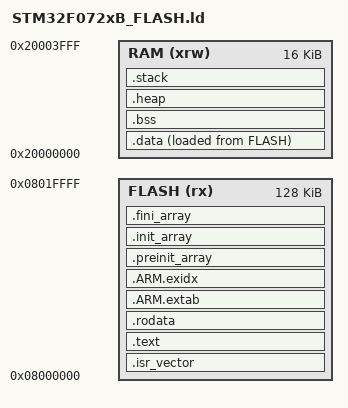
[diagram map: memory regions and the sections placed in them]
ENTRY(Reset_Handler)

MEMORY
{
  FLASH (rx)  : ORIGIN = 0x08000000, LENGTH = 128K
  RAM (xrw)   : ORIGIN = 0x20000000, LENGTH = 16K
}

_estack = ORIGIN(RAM) + LENGTH(RAM);

SECTIONS
{
  .isr_vector :
  {
    . = ALIGN(4);
    KEEP(*(.isr_vector))
    . = ALIGN(4);
  } > FLASH

  .text :
  {
    . = ALIGN(4);
    *(.text .text*)
    *(.glue_7 .glue_7t)
    *(.eh_frame)
    KEEP(*(.init))
    KEEP(*(.fini))
    . = ALIGN(4);
    _etext = .;
  } > FLASH

  .rodata :
  {
    . = ALIGN(4);
    *(.rodata .rodata*)
    . = ALIGN(4);
  } > FLASH

  .ARM.extab :
  {
    . = ALIGN(4);
    *(.ARM.extab* .gnu.linkonce.armextab.*)
    . = ALIGN(4);
  } > FLASH

  .ARM.exidx :
  {
    . = ALIGN(4);
    __exidx_start = .;
    *(.ARM.exidx* .gnu.linkonce.armexidx.*)
    __exidx_end = .;
    . = ALIGN(4);
  } > FLASH

  .preinit_array :
  {
    . = ALIGN(4);
    PROVIDE_HIDDEN(__preinit_array_start = .);
    KEEP(*(.preinit_array*))
    PROVIDE_HIDDEN(__preinit_array_end = .);
    . = ALIGN(4);
  } > FLASH

  .init_array :
  {
    . = ALIGN(4);
    PROVIDE_HIDDEN(__init_array_start = .);
    KEEP(*(SORT(.init_array.*)))
    KEEP(*(.init_array*))
    PROVIDE_HIDDEN(__init_array_end = .);
    . = ALIGN(4);
  } > FLASH

  .fini_array :
  {
    . = ALIGN(4);
    PROVIDE_HIDDEN(__fini_array_start = .);
    KEEP(*(SORT(.fini_array.*)))
    KEEP(*(.fini_array*))
    PROVIDE_HIDDEN(__fini_array_end = .);
    . = ALIGN(4);
  } > FLASH

  _sidata = LOADADDR(.data);
  .data :
  {
    . = ALIGN(4);
    _sdata = .;
    *(.data .data*)
    . = ALIGN(4);
    _edata = .;
  } > RAM AT > FLASH

  .bss :
  {
    . = ALIGN(4);
    _sbss = .;
    *(.bss .bss*)
    *(COMMON)
    . = ALIGN(4);
    _ebss = .;
  } > RAM
  .heap (NOLOAD) :
  {
    . = ALIGN(8);
    __heap_start = .;
    . = ORIGIN(RAM) + LENGTH(RAM) - 2048;
    __heap_end = .;
  } > RAM

  .stack (NOLOAD) :
  {
    . = . + 2048;
  } > RAM
  ASSERT(__heap_end - __heap_start >= 1024, "Insufficient heap before 2 KiB stack")

}
